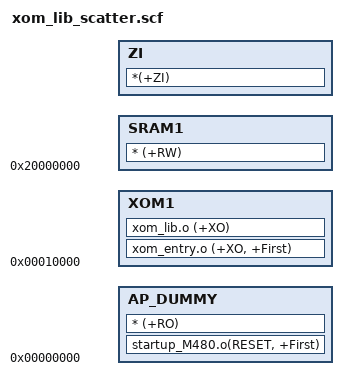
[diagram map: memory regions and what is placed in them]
AP_DUMMY 0x00000000
{
    AP_DUMMY +0
    {
        startup_M480.o(RESET, +First)
        * (+RO)    
    }

  SRAM1 0x20000000
    {  
        * (+RW)
    }

  ZI +0
  {
    *(+ZI)
  }

}

XOM1 0x10000
{
    XOM1 +0
    {
    	xom_entry.o (+XO, +First)
    	xom_lib.o (+XO)
    }
}
